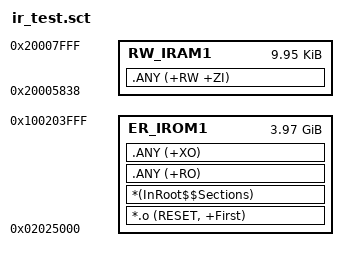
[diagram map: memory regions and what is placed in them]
; *************************************************************
; *** Scatter-Loading Description File generated by uVision ***
; *************************************************************

LR_IROM1 0x02025000 0xFE1DF000  {    ; load region size_region
  ER_IROM1 0x02025000 0xFE1DF000  {  ; load address = execution address
   *.o (RESET, +First)
   *(InRoot$$Sections)
   .ANY (+RO)
   .ANY (+XO)
  }
  RW_IRAM1 0x20005838 0x000027C8  {  ; RW data
   .ANY (+RW +ZI)
  }
}

